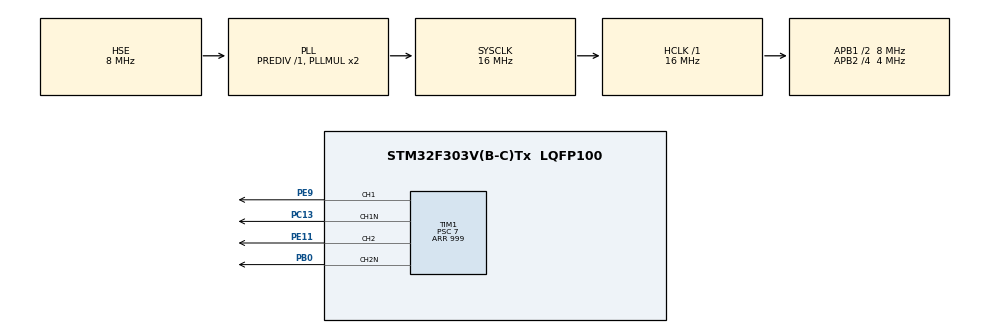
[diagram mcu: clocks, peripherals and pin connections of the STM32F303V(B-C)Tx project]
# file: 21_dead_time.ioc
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Dma.Request0=TIM1_CH1
Dma.Request1=TIM1_CH2
Dma.TIM1_CH1.0.Direction=DMA_MEMORY_TO_PERIPH
Dma.TIM1_CH1.0.Instance=DMA1_Channel2
Dma.TIM1_CH1.0.MemDataAlignment=DMA_MDATAALIGN_HALFWORD
Dma.TIM1_CH1.0.MemInc=DMA_MINC_ENABLE
Dma.TIM1_CH1.0.Mode=DMA_CIRCULAR
Dma.TIM1_CH1.0.PeriphDataAlignment=DMA_PDATAALIGN_HALFWORD
Dma.TIM1_CH1.0.PeriphInc=DMA_PINC_DISABLE
Dma.TIM1_CH1.0.Priority=DMA_PRIORITY_LOW
Dma.TIM1_CH2.1.Direction=DMA_MEMORY_TO_PERIPH
Dma.TIM1_CH2.1.Instance=DMA1_Channel3
Dma.TIM1_CH2.1.MemDataAlignment=DMA_MDATAALIGN_HALFWORD
Dma.TIM1_CH2.1.MemInc=DMA_MINC_ENABLE
Dma.TIM1_CH2.1.Mode=DMA_CIRCULAR
Dma.TIM1_CH2.1.PeriphDataAlignment=DMA_PDATAALIGN_HALFWORD
Dma.TIM1_CH2.1.PeriphInc=DMA_PINC_DISABLE
Dma.TIM1_CH2.1.Priority=DMA_PRIORITY_LOW
Mcu.Family=STM32F3
Mcu.Name=STM32F303V(B-C)Tx
Mcu.Package=LQFP100
NVIC.DMA1_Channel2_IRQn=true\:0\:0\:false\:false\:true\:false
NVIC.DMA1_Channel3_IRQn=true\:0\:0\:false\:false\:true\:false
NVIC.PriorityGroup=NVIC_PRIORITYGROUP_4
PB0.Mode=PWM Generation2 CH2 CH2N
PB0.Signal=TIM1_CH2N
PC13.Mode=PWM Generation1 CH1 CH1N
PC13.Signal=TIM1_CH1N
PE11.Signal=S_TIM1_CH2
PE9.Signal=S_TIM1_CH1
PF0-OSC_IN.Mode=HSE-External-Oscillator
PF0-OSC_IN.Signal=RCC_OSC_IN
PF1-OSC_OUT.Mode=HSE-External-Oscillator
PF1-OSC_OUT.Signal=RCC_OSC_OUT
ProjectManager.HeapSize=0x200
ProjectManager.StackSize=0x400
ProjectManager.TargetToolchain=SW4STM32
RCC.AHBFreq_Value=16000000
RCC.APB1CLKDivider=RCC_HCLK_DIV2
RCC.APB1Freq_Value=8000000
RCC.APB1TimFreq_Value=16000000
RCC.APB2CLKDivider=RCC_HCLK_DIV4
RCC.APB2Freq_Value=4000000
RCC.APB2TimFreq_Value=8000000
RCC.CortexFreq_Value=16000000
RCC.HCLKFreq_Value=16000000
RCC.HSE_VALUE=8000000
RCC.HSI_VALUE=8000000
RCC.LSE_VALUE=32768
RCC.PLLSourceVirtual=RCC_PLLSOURCE_HSE
RCC.SYSCLKFreq_VALUE=16000000
RCC.SYSCLKSourceVirtual=RCC_SYSCLKSOURCE_PLLCLK
RCC.USBFreq_Value=16000000
SH.S_TIM1_CH1.0=TIM1_CH1,PWM Generation1 CH1 CH1N
SH.S_TIM1_CH2.0=TIM1_CH2,PWM Generation2 CH2 CH2N
TIM1.Channel-PWM\ Generation1\ CH1\ CH1N=TIM_CHANNEL_1
TIM1.Channel-PWM\ Generation2\ CH2\ CH2N=TIM_CHANNEL_2
TIM1.DeadTime=200
TIM1.OCMode_PWM-PWM\ Generation2\ CH2\ CH2N=TIM_OCMODE_PWM2
TIM1.OCNIdleState_1=TIM_OCNIDLESTATE_RESET
TIM1.OCNIdleState_2=TIM_OCNIDLESTATE_SET
TIM1.OCNPolarity_1=TIM_OCNPOLARITY_LOW
TIM1.OCNPolarity_2=TIM_OCNPOLARITY_LOW
TIM1.OCPolarity_2=TIM_OCPOLARITY_HIGH
TIM1.Period=999
TIM1.Prescaler=7
TIM1.Pulse-PWM\ Generation1\ CH1\ CH1N=499
TIM1.Pulse-PWM\ Generation2\ CH2\ CH2N=499
VP_TIM1_VS_ClockSourceINT.Mode=Internal
board=21_dead_time

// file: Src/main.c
/**
  ******************************************************************************
  * @file           : main.c
  * @brief          : Main program body
  ******************************************************************************
  ** This notice applies to any and all portions of this file
  * that are not between comment pairs USER CODE BEGIN and
  * USER CODE END. Other portions of this file, whether
  * inserted by the user or by software development tools
  * are owned by their respective copyright owners.
  *
  * COPYRIGHT(c) 2018 STMicroelectronics
  *
  * Redistribution and use in source and binary forms, with or without modification,
  * are permitted provided that the following conditions are met:
  *   1. Redistributions of source code must retain the above copyright notice,
  *      this list of conditions and the following disclaimer.
  *   2. Redistributions in binary form must reproduce the above copyright notice,
  *      this list of conditions and the following disclaimer in the documentation
  *      and/or other materials provided with the distribution.
  *   3. Neither the name of STMicroelectronics nor the names of its contributors
  *      may be used to endorse or promote products derived from this software
  *      without specific prior written permission.
  *
  * THIS SOFTWARE IS PROVIDED BY THE COPYRIGHT HOLDERS AND CONTRIBUTORS "AS IS"
  * AND ANY EXPRESS OR IMPLIED WARRANTIES, INCLUDING, BUT NOT LIMITED TO, THE
  * IMPLIED WARRANTIES OF MERCHANTABILITY AND FITNESS FOR A PARTICULAR PURPOSE ARE
  * DISCLAIMED. IN NO EVENT SHALL THE COPYRIGHT HOLDER OR CONTRIBUTORS BE LIABLE
  * FOR ANY DIRECT, INDIRECT, INCIDENTAL, SPECIAL, EXEMPLARY, OR CONSEQUENTIAL
  * DAMAGES (INCLUDING, BUT NOT LIMITED TO, PROCUREMENT OF SUBSTITUTE GOODS OR
  * SERVICES; LOSS OF USE, DATA, OR PROFITS; OR BUSINESS INTERRUPTION) HOWEVER
  * CAUSED AND ON ANY THEORY OF LIABILITY, WHETHER IN CONTRACT, STRICT LIABILITY,
  * OR TORT (INCLUDING NEGLIGENCE OR OTHERWISE) ARISING IN ANY WAY OUT OF THE USE
  * OF THIS SOFTWARE, EVEN IF ADVISED OF THE POSSIBILITY OF SUCH DAMAGE.
  *
  ******************************************************************************
  */
#include "main.h"
#include "stm32f3xx_hal.h"

TIM_HandleTypeDef htim1;

/* USER CODE BEGIN PV */
/* Private variables ---------------------------------------------------------*/
volatile uint16_t Duty = 0; // Wypelnienie sygnalu PWM 0-999
/* USER CODE END PV */

void SystemClock_Config(void);
static void MX_GPIO_Init(void);
static void MX_TIM1_Init(void);
void HAL_TIM_MspPostInit(TIM_HandleTypeDef *htim);

/* USER CODE BEGIN PFP */
/* Private function prototypes -----------------------------------------------*/

/* USER CODE END PFP */

int main(void)
{

  /* MCU Configuration----------------------------------------------------------*/

  /* Reset of all peripherals, Initializes the Flash interface and the Systick. */
  HAL_Init();

  /* Configure the system clock */
  SystemClock_Config();

  /* Initialize all configured peripherals */
  MX_GPIO_Init();
  MX_TIM1_Init();
  /* USER CODE BEGIN 2 */
  HAL_TIM_PWM_Start(&htim1, TIM_CHANNEL_1);
  HAL_TIMEx_PWMN_Start(&htim1, TIM_CHANNEL_1); // turn on complementary channel

  HAL_TIM_PWM_Start(&htim1, TIM_CHANNEL_2);
  HAL_TIMEx_PWMN_Start(&htim1, TIM_CHANNEL_2); // turn on complementary channel

  //HAL_Tim_PWM_DMA
  /* USER CODE END 2 */
  HAL_TIM_Base_Start_IT(&htim6);

  /* Infinite loop */
  while (1)
  {

  }

}

void SystemClock_Config(void)
{

  RCC_OscInitTypeDef RCC_OscInitStruct;
  RCC_ClkInitTypeDef RCC_ClkInitStruct;
  RCC_PeriphCLKInitTypeDef PeriphClkInit;

    /**Initializes the CPU, AHB and APB busses clocks
    */
  RCC_OscInitStruct.OscillatorType = RCC_OSCILLATORTYPE_HSE;
  RCC_OscInitStruct.HSEState = RCC_HSE_ON;
  RCC_OscInitStruct.HSEPredivValue = RCC_HSE_PREDIV_DIV1;
  RCC_OscInitStruct.HSIState = RCC_HSI_ON;
  RCC_OscInitStruct.PLL.PLLState = RCC_PLL_ON;
  RCC_OscInitStruct.PLL.PLLSource = RCC_PLLSOURCE_HSE;
  RCC_OscInitStruct.PLL.PLLMUL = RCC_PLL_MUL2;
  if (HAL_RCC_OscConfig(&RCC_OscInitStruct) != HAL_OK)
  {
    _Error_Handler(__FILE__, __LINE__);
  }

    /**Initializes the CPU, AHB and APB busses clocks
    */
  RCC_ClkInitStruct.ClockType = RCC_CLOCKTYPE_HCLK|RCC_CLOCKTYPE_SYSCLK
                              |RCC_CLOCKTYPE_PCLK1|RCC_CLOCKTYPE_PCLK2;
  RCC_ClkInitStruct.SYSCLKSource = RCC_SYSCLKSOURCE_PLLCLK;
  RCC_ClkInitStruct.AHBCLKDivider = RCC_SYSCLK_DIV1;
  RCC_ClkInitStruct.APB1CLKDivider = RCC_HCLK_DIV2;
  RCC_ClkInitStruct.APB2CLKDivider = RCC_HCLK_DIV4;

  if (HAL_RCC_ClockConfig(&RCC_ClkInitStruct, FLASH_LATENCY_0) != HAL_OK)
  {
    _Error_Handler(__FILE__, __LINE__);
  }

  PeriphClkInit.PeriphClockSelection = RCC_PERIPHCLK_TIM1;
  PeriphClkInit.Tim1ClockSelection = RCC_TIM1CLK_HCLK;
  if (HAL_RCCEx_PeriphCLKConfig(&PeriphClkInit) != HAL_OK)
  {
    _Error_Handler(__FILE__, __LINE__);
  }

    /**Configure the Systick interrupt time
    */
  HAL_SYSTICK_Config(HAL_RCC_GetHCLKFreq()/1000);

    /**Configure the Systick
    */
  HAL_SYSTICK_CLKSourceConfig(SYSTICK_CLKSOURCE_HCLK);

  /* SysTick_IRQn interrupt configuration */
  HAL_NVIC_SetPriority(SysTick_IRQn, 0, 0);
}

/* TIM1 init function */
static void MX_TIM1_Init(void)
{

  TIM_ClockConfigTypeDef sClockSourceConfig;
  TIM_MasterConfigTypeDef sMasterConfig;
  TIM_OC_InitTypeDef sConfigOC;
  TIM_BreakDeadTimeConfigTypeDef sBreakDeadTimeConfig;

  htim1.Instance = TIM1;
  htim1.Init.Prescaler = 7;
  htim1.Init.CounterMode = TIM_COUNTERMODE_UP;
  htim1.Init.Period = 999;
  htim1.Init.ClockDivision = TIM_CLOCKDIVISION_DIV1;
  htim1.Init.RepetitionCounter = 0;
  htim1.Init.AutoReloadPreload = TIM_AUTORELOAD_PRELOAD_DISABLE;
  if (HAL_TIM_Base_Init(&htim1) != HAL_OK)
  {
    _Error_Handler(__FILE__, __LINE__);
  }

  sClockSourceConfig.ClockSource = TIM_CLOCKSOURCE_INTERNAL;
  if (HAL_TIM_ConfigClockSource(&htim1, &sClockSourceConfig) != HAL_OK)
  {
    _Error_Handler(__FILE__, __LINE__);
  }

  if (HAL_TIM_PWM_Init(&htim1) != HAL_OK)
  {
    _Error_Handler(__FILE__, __LINE__);
  }

  sMasterConfig.MasterOutputTrigger = TIM_TRGO_RESET;
  sMasterConfig.MasterOutputTrigger2 = TIM_TRGO2_RESET;
  sMasterConfig.MasterSlaveMode = TIM_MASTERSLAVEMODE_DISABLE;
  if (HAL_TIMEx_MasterConfigSynchronization(&htim1, &sMasterConfig) != HAL_OK)
  {
    _Error_Handler(__FILE__, __LINE__);
  }

  sConfigOC.OCMode = TIM_OCMODE_PWM1;
  sConfigOC.Pulse = 499;
  sConfigOC.OCPolarity = TIM_OCPOLARITY_HIGH;
  sConfigOC.OCNPolarity = TIM_OCNPOLARITY_LOW;
  sConfigOC.OCFastMode = TIM_OCFAST_DISABLE;
  sConfigOC.OCIdleState = TIM_OCIDLESTATE_RESET;
  sConfigOC.OCNIdleState = TIM_OCNIDLESTATE_RESET;
  if (HAL_TIM_PWM_ConfigChannel(&htim1, &sConfigOC, TIM_CHANNEL_1) != HAL_OK)
  {
    _Error_Handler(__FILE__, __LINE__);
  }

  sConfigOC.OCMode = TIM_OCMODE_PWM2;
  sConfigOC.OCNIdleState = TIM_OCNIDLESTATE_SET;
  if (HAL_TIM_PWM_ConfigChannel(&htim1, &sConfigOC, TIM_CHANNEL_2) != HAL_OK)
  {
    _Error_Handler(__FILE__, __LINE__);
  }

  sBreakDeadTimeConfig.OffStateRunMode = TIM_OSSR_DISABLE;
  sBreakDeadTimeConfig.OffStateIDLEMode = TIM_OSSI_DISABLE;
  sBreakDeadTimeConfig.LockLevel = TIM_LOCKLEVEL_OFF;
  sBreakDeadTimeConfig.DeadTime = 200;
  sBreakDeadTimeConfig.BreakState = TIM_BREAK_DISABLE;
  sBreakDeadTimeConfig.BreakPolarity = TIM_BREAKPOLARITY_HIGH;
  sBreakDeadTimeConfig.BreakFilter = 0;
  sBreakDeadTimeConfig.Break2State = TIM_BREAK2_DISABLE;
  sBreakDeadTimeConfig.Break2Polarity = TIM_BREAK2POLARITY_HIGH;
  sBreakDeadTimeConfig.Break2Filter = 0;
  sBreakDeadTimeConfig.AutomaticOutput = TIM_AUTOMATICOUTPUT_DISABLE;
  if (HAL_TIMEx_ConfigBreakDeadTime(&htim1, &sBreakDeadTimeConfig) != HAL_OK)
  {
    _Error_Handler(__FILE__, __LINE__);
  }

  HAL_TIM_MspPostInit(&htim1);

}

/** Configure pins as
        * Analog
        * Input
        * Output
        * EVENT_OUT
        * EXTI
*/
static void MX_GPIO_Init(void)
{

  /* GPIO Ports Clock Enable */
  __HAL_RCC_GPIOC_CLK_ENABLE();
  __HAL_RCC_GPIOF_CLK_ENABLE();
  __HAL_RCC_GPIOB_CLK_ENABLE();
  __HAL_RCC_GPIOE_CLK_ENABLE();

}

void _Error_Handler(char *file, int line)
{
  while(1)
  {
  }
}

/************************ (C) COPYRIGHT STMicroelectronics *****END OF FILE****/
